# STM32U5F7xx register map
File version: 1.0
Registers are 32-bit, read-write, reset 0x0 unless marked. A register's access mark holds for its fields unless they carry their own. Offsets are from the block's base; [hi:lo] are bit positions; {n}, {i} and the like mark numbered series; 'fields as' and 'values as' point back to an identical list.

## GPDMA1 — DMA Controller
Base 0x40020000
Same registers: GPDMA1_S 0x50020000
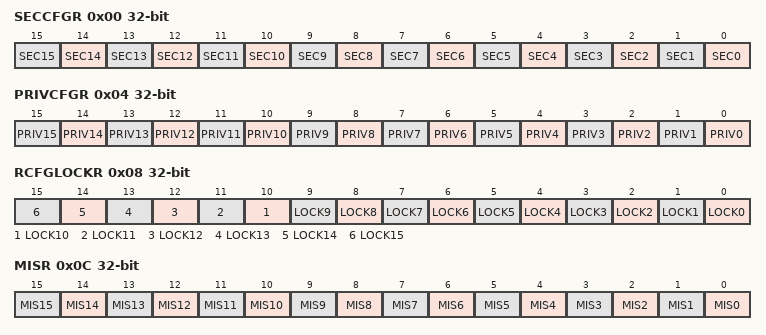
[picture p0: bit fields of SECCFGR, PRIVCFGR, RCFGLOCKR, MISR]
0x00 SECCFGR — DMA secure configuration register
  [n] SEC{n} (n=0..15) — Secure State of Channel {n}
0x04 PRIVCFGR — DMA privileged configuration register
  [n] PRIV{n} (n=0..15) — Privileged State of Channel {n}
0x08 RCFGLOCKR — DMA lock configuration register
  [n] LOCK{n} (n=0..15) — Lock the configuration of Channel {n}
0x0C MISR — DMA non secure masked interrupt status register
  [n] MIS{n} (n=0..15) — Masked Interrupt State of Non-Secure Channel {n}
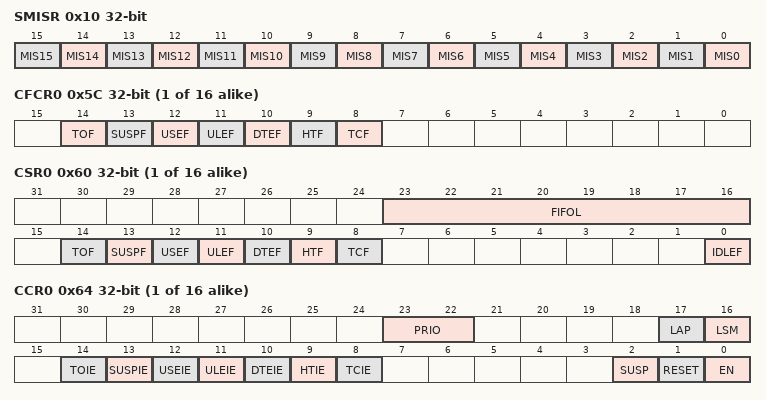
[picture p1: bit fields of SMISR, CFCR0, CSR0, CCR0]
0x10 SMISR — DMA secure masked interrupt status register
  [n] MIS{n} (n=0..15) — Masked Interrupt State of Secure Channel {n}
{0x50+0x80*i} CLBAR{i} (i=0..15) — DMA channel x linked-list base address register
  [31:16] LBA — Linked-list Base Address of DMA channel x
{0x5C+0x80*i} CFCR{i} (i=0..15) — DMA channel x flag clear register
  [14] TOF — Trigger overrun flag clear
  [13] SUSPF — Completed suspension flag clear
  [12] USEF — User setting error flag clear
  [11] ULEF — Update linked-list item error flag clear
  [10] DTEF — Data transfer error flag clear
  [9] HTF — Half transfer complete flag clear
  [8] TCF — Transfer complete flag clear
{0x60+0x80*i} CSR{i} (i=0..15) — DMA channel x flag status register
  [23:16] FIFOL — Monitored FIFO level in bytes
  [14] TOF — Trigger overrun flag
  [13] SUSPF — Completed suspension flag
  [12] USEF — User setting error flag
  [11] ULEF — Update linked-list item error flag
  [10] DTEF — Data transfer error flag
  [9] HTF — Half transfer complete flag
  [8] TCF — Transfer complete flag
  [0] IDLEF — Idle flag
{0x64+0x80*i} CCR{i} (i=0..15) — DMA channel x control register
  [23:22] PRIO — Priority level
  [17] LAP — Linked-list allocated port
  [16] LSM — Link step mode
  [14] TOIE — Trigger overrun interrupt enable
  [13] SUSPIE — Completed suspension interrupt enable
  [12] USEIE — User setting error interrupt enable
  [11] ULEIE — Update linked-list item error interrupt enable
  [10] DTEIE — Data transfer error interrupt enable
  [9] HTIE — Half transfer complete interrupt enable
  [8] TCIE — Transfer complete interrupt enable
  [2] SUSP — Channel suspend
  [1] RESET — Channel reset
  [0] EN — Channel enable
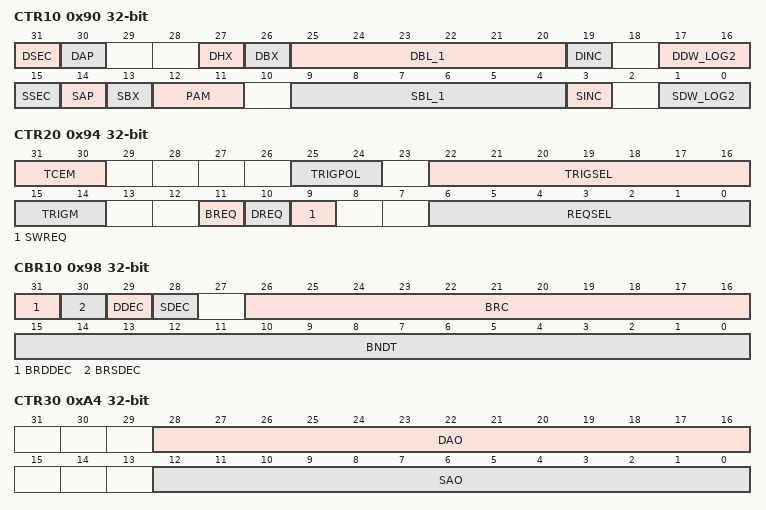
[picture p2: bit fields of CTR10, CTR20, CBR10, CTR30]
0x90 CTR10 — DMA channel x transfer register 1
  [31] DSEC — Security attribute of the DMA transfer from the destination
  [30] DAP — Destination allocated port
  [27] DHX — Destination half-word exchange
  [26] DBX — Destination byte exchange
  [25:20] DBL_1 — Destination burst length minus 1
  [19] DINC — Destination incrementing burst
  [17:16] DDW_LOG2 — Binary logarithm of the destination data width of a burst
  [15] SSEC — Security attribute of the DMA transfer from the source
  [14] SAP — Source allocated port
  [13] SBX — Source byte exchange within the unaligned half-word of each source word
  [12:11] PAM — Padding / alignment mode
  [9:4] SBL_1 — Source burst length minus 1
  [3] SINC — Source incrementing burst
  [1:0] SDW_LOG2 — Binary logarithm of the source data width of a burst
0x94 CTR20 — DMA channel x transfer register 2
  [31:30] TCEM — Transfer complete event mode
  [25:24] TRIGPOL — Trigger event polarity
  [22:16] TRIGSEL — Trigger event input selection
  [15:14] TRIGM — Trigger mode
  [11] BREQ — Block hardware request
  [10] DREQ — Destination hardware request
  [9] SWREQ — Software request
  [6:0] REQSEL — DMA hardware request selection
0x98 CBR10 — DMA channel x block register 1
  [31] BRDDEC — Block repeat destination address decrement
  [30] BRSDEC — Block repeat source address decrement
  [29] DDEC — Destination address decrement
  [28] SDEC — Source address decrement
  [26:16] BRC — Block repeat counter
  [15:0] BNDT — Block number of data bytes to transfer from the source
{0x9C+0x80*i} CSAR{i} (i=0..15) — DMA channel x source address register
  [31:0] SA — Source Address
{0xA0+0x80*i} CDAR{i} (i=0..15) — DMA channel x destination address register
  [31:0] DA — Destination address
0xA4 CTR30 — DMA channel x transfer register 3
  [28:16] DAO — Destination address offset increment
  [12:0] SAO — Source address offset increment
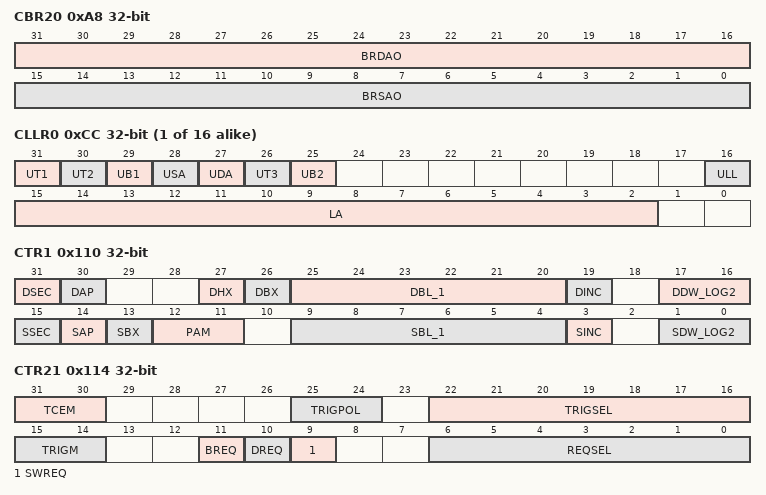
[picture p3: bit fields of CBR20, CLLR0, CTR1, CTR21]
0xA8 CBR20 — DMA channel x block register 2
  [31:16] BRDAO — Block repeated destination address offset
  [15:0] BRSAO — Block repeated source address offset
{0xCC+0x80*i} CLLR{i} (i=0..15) — DMA channel x linked-list address register
  [31] UT1 — Update transfer register 1 from SRAM
  [30] UT2 — Update transfer register 2 from SRAM
  [29] UB1 — Update block register 1 from SRAM
  [28] USA — Update source address register from SRAM
  [27] UDA — Update destination address register from SRAM
  [26] UT3 — Update transfer register 3 from SRAM
  [25] UB2 — Update block register 2 from memory
  [16] ULL — Update link address register from memory
  [15:2] LA — Pointer to the next linked-list data structure
0x110 CTR1 — DMA channel x transfer register 1
  fields as CTR10
0x114 CTR21 — DMA channel x transfer register 2
  fields as CTR20
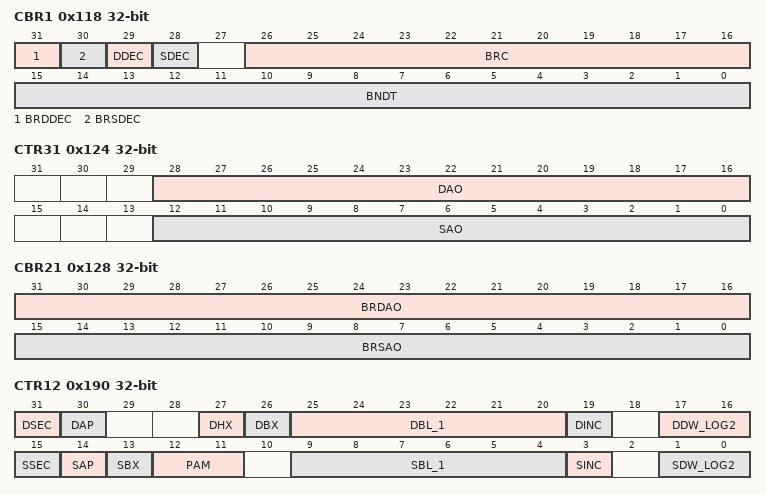
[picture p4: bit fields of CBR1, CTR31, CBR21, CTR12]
0x118 CBR1 — DMA channel x block register 1
  fields as CBR10
0x124 CTR31 — DMA channel x transfer register 3
  fields as CTR30
0x128 CBR21 — DMA channel x block register 2
  fields as CBR20
0x190 CTR12 — DMA channel x transfer register 1
  fields as CTR10
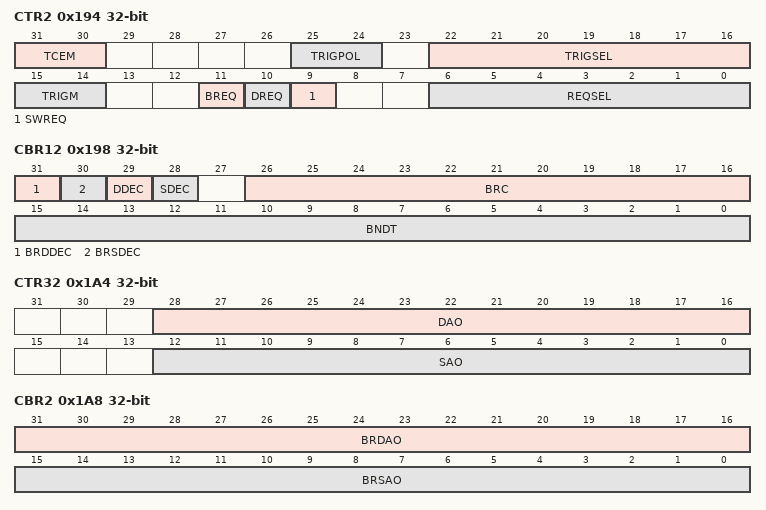
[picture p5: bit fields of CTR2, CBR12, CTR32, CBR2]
0x194 CTR2 — DMA channel x transfer register 2
  fields as CTR20
0x198 CBR12 — DMA channel x block register 1
  fields as CBR10
0x1A4 CTR32 — DMA channel x transfer register 3
  fields as CTR30
0x1A8 CBR2 — DMA channel x block register 2
  fields as CBR20
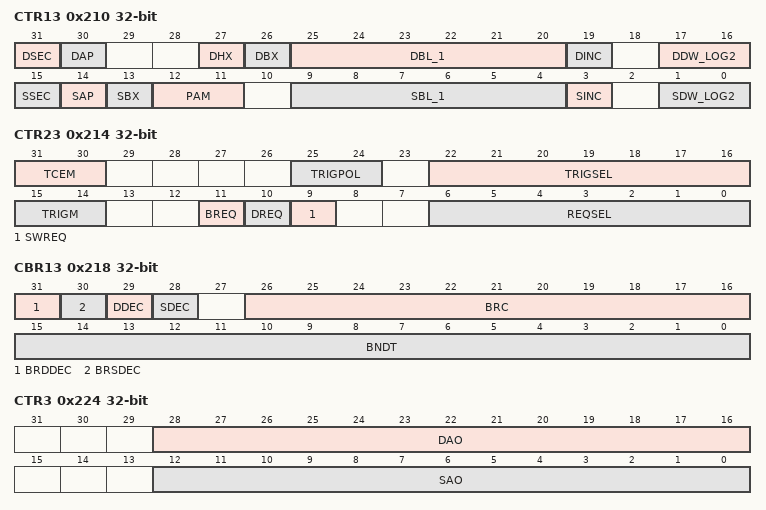
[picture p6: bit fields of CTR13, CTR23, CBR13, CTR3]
0x210 CTR13 — DMA channel x transfer register 1
  fields as CTR10
0x214 CTR23 — DMA channel x transfer register 2
  fields as CTR20
0x218 CBR13 — DMA channel x block register 1
  fields as CBR10
0x224 CTR3 — DMA channel x transfer register 3
  fields as CTR30
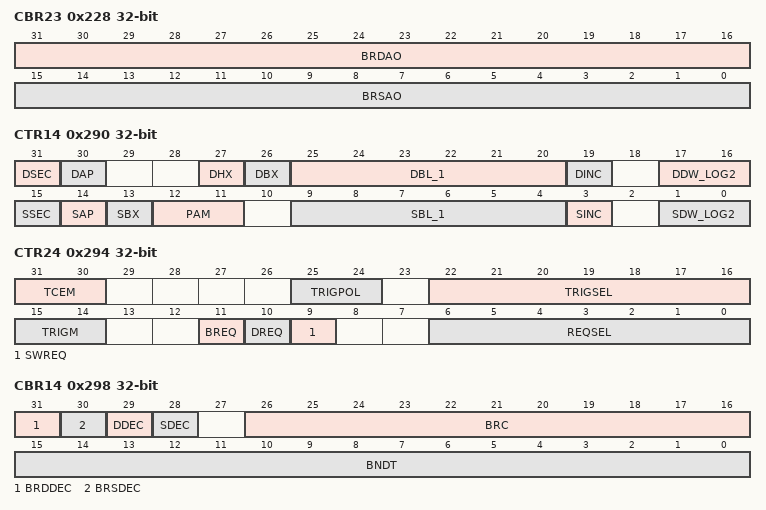
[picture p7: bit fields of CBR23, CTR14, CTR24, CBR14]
0x228 CBR23 — DMA channel x block register 2
  fields as CBR20
0x290 CTR14 — DMA channel x transfer register 1
  fields as CTR10
0x294 CTR24 — DMA channel x transfer register 2
  fields as CTR20
0x298 CBR14 — DMA channel x block register 1
  fields as CBR10
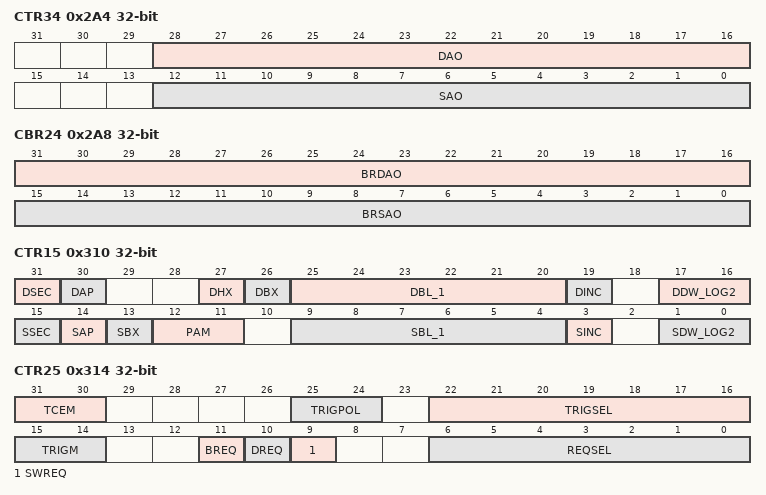
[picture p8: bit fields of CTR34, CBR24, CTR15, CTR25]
0x2A4 CTR34 — DMA channel x transfer register 3
  fields as CTR30
0x2A8 CBR24 — DMA channel x block register 2
  fields as CBR20
0x310 CTR15 — DMA channel x transfer register 1
  fields as CTR10
0x314 CTR25 — DMA channel x transfer register 2
  fields as CTR20
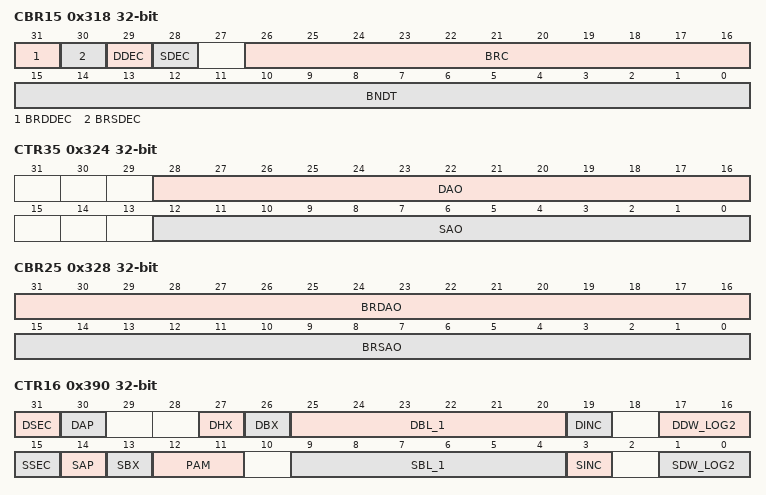
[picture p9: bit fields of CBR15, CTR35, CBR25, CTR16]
0x318 CBR15 — DMA channel x block register 1
  fields as CBR10
0x324 CTR35 — DMA channel x transfer register 3
  fields as CTR30
0x328 CBR25 — DMA channel x block register 2
  fields as CBR20
0x390 CTR16 — DMA channel x transfer register 1
  fields as CTR10
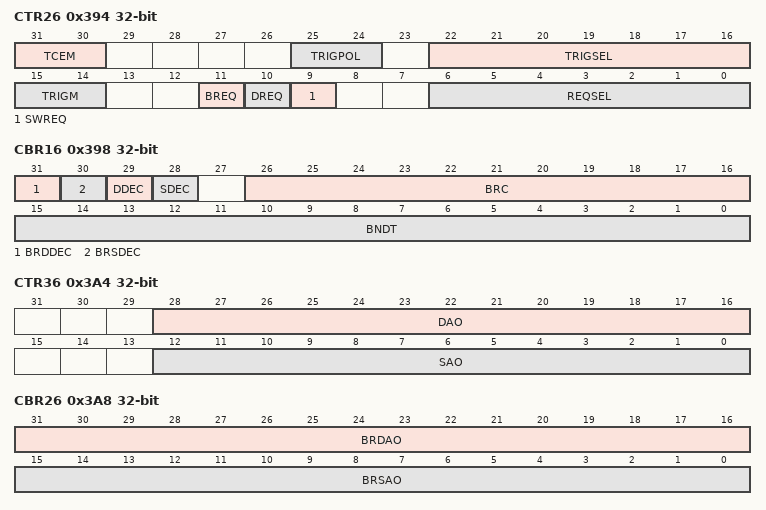
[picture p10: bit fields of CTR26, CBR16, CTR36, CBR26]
0x394 CTR26 — DMA channel x transfer register 2
  fields as CTR20
0x398 CBR16 — DMA channel x block register 1
  fields as CBR10
0x3A4 CTR36 — DMA channel x transfer register 3
  fields as CTR30
0x3A8 CBR26 — DMA channel x block register 2
  fields as CBR20
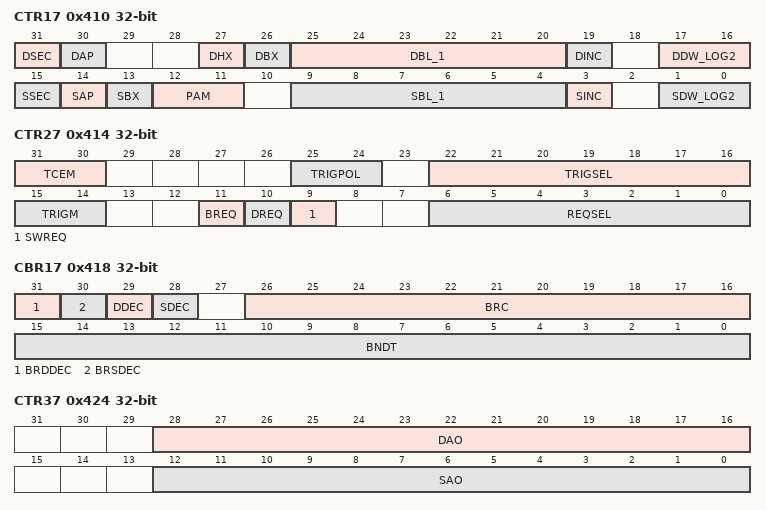
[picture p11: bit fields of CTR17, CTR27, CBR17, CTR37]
0x410 CTR17 — DMA channel x transfer register 1
  fields as CTR10
0x414 CTR27 — DMA channel x transfer register 2
  fields as CTR20
0x418 CBR17 — DMA channel x block register 1
  fields as CBR10
0x424 CTR37 — DMA channel x transfer register 3
  fields as CTR30
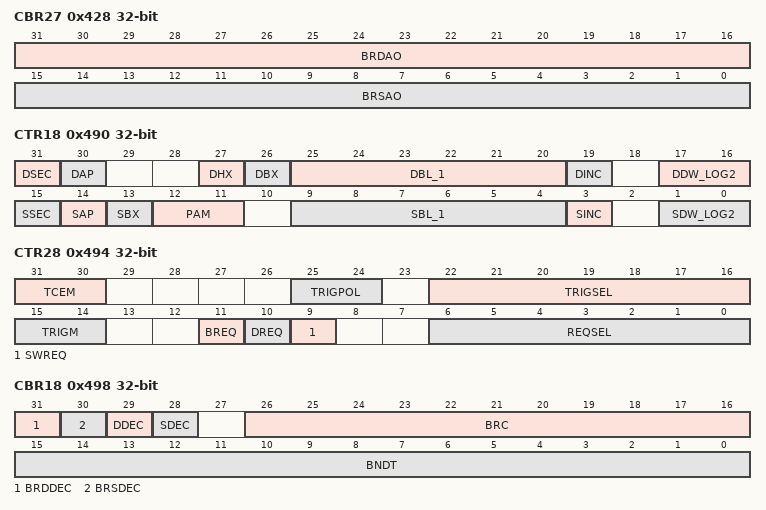
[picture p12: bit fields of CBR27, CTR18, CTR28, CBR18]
0x428 CBR27 — DMA channel x block register 2
  fields as CBR20
0x490 CTR18 — DMA channel x transfer register 1
  fields as CTR10
0x494 CTR28 — DMA channel x transfer register 2
  fields as CTR20
0x498 CBR18 — DMA channel x block register 1
  fields as CBR10
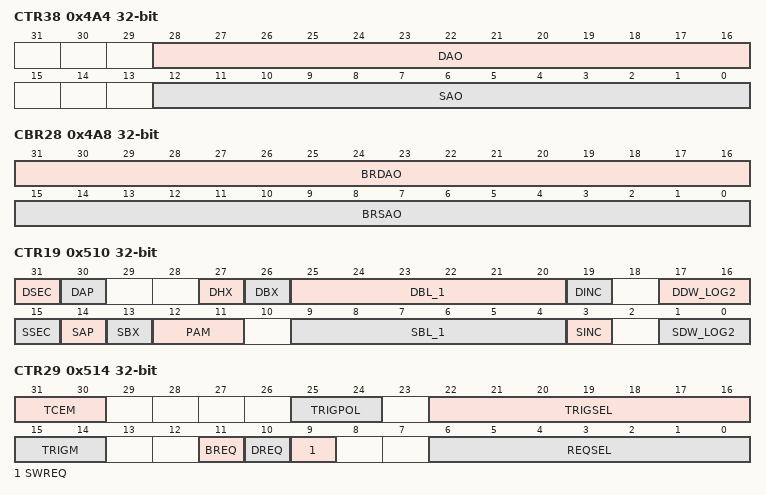
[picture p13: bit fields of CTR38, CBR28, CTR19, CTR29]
0x4A4 CTR38 — DMA channel x transfer register 3
  fields as CTR30
0x4A8 CBR28 — DMA channel x block register 2
  fields as CBR20
0x510 CTR19 — DMA channel x transfer register 1
  fields as CTR10
0x514 CTR29 — DMA channel x transfer register 2
  fields as CTR20
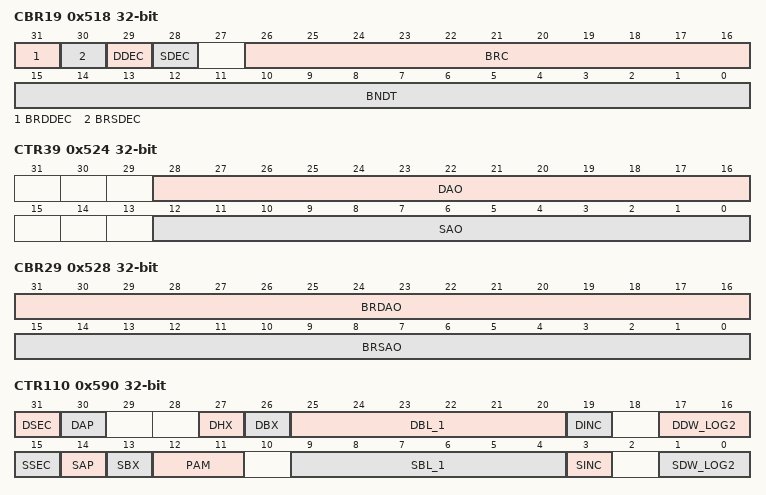
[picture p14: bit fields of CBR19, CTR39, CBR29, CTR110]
0x518 CBR19 — DMA channel x block register 1
  fields as CBR10
0x524 CTR39 — DMA channel x transfer register 3
  fields as CTR30
0x528 CBR29 — DMA channel x block register 2
  fields as CBR20
0x590 CTR110 — DMA channel x transfer register 1
  fields as CTR10
0x594 CTR210 — DMA channel x transfer register 2
  fields as CTR20
0x598 CBR110 — DMA channel x block register 1
  fields as CBR10
0x5A4 CTR310 — DMA channel x transfer register 3
  fields as CTR30
0x5A8 CBR210 — DMA channel x block register 2
  fields as CBR20
0x610 CTR111 — DMA channel x transfer register 1
  fields as CTR10
0x614 CTR211 — DMA channel x transfer register 2
  fields as CTR20
0x618 CBR111 — DMA channel x block register 1
  fields as CBR10
0x624 CTR311 — DMA channel x transfer register 3
  fields as CTR30
0x628 CBR211 — DMA channel x block register 2
  fields as CBR20
0x690 CTR112 — DMA channel x transfer register 1
  fields as CTR10
0x694 CTR212 — DMA channel x transfer register 2
  fields as CTR20
0x698 CBR112 — DMA channel x block register 1
  fields as CBR10
0x6A4 CTR312 — DMA channel x transfer register 3
  fields as CTR30
0x6A8 CBR212 — DMA channel x block register 2
  fields as CBR20
0x710 CTR113 — DMA channel x transfer register 1
  fields as CTR10
0x714 CTR213 — DMA channel x transfer register 2
  fields as CTR20
0x718 CBR113 — DMA channel x block register 1
  fields as CBR10
0x724 CTR313 — DMA channel x transfer register 3
  fields as CTR30
0x728 CBR213 — DMA channel x block register 2
  fields as CBR20
0x790 CTR114 — DMA channel x transfer register 1
  fields as CTR10
0x794 CTR214 — DMA channel x transfer register 2
  fields as CTR20
0x798 CBR114 — DMA channel x block register 1
  fields as CBR10
0x7A4 CTR314 — DMA channel x transfer register 3
  fields as CTR30
0x7A8 CBR214 — DMA channel x block register 2
  fields as CBR20
0x810 CTR115 — DMA channel x transfer register 1
  fields as CTR10
0x814 CTR215 — DMA channel x transfer register 2
  fields as CTR20
0x818 CBR115 — DMA channel x block register 1
  fields as CBR10
0x824 CTR315 — DMA channel x transfer register 3
  fields as CTR30
0x828 CBR215 — DMA channel x block register 2
  fields as CBR20

## LPDMA1 — DMA Controller
Base 0x46025000
Same registers: LPDMA1_S 0x56025000
Registers as GPDMA1, without CLBAR{n} (n=4..15), CFCR{n} (n=4..15), CSR{n} (n=4..15), CCR{n} (n=4..15), CTR{n} (n=14..19), CTR{n} (n=24..29), CBR{n} (n=14..19), CSAR{n} (n=4..15), CDAR{n} (n=4..15), CTR{n} (n=34..39), CBR{n} (n=24..29), CLLR{n} (n=4..15), CTR{n} (n=110..115), CTR{n} (n=210..215), CBR{n} (n=110..115), CTR{n} (n=310..315), CBR{n} (n=210..215).
